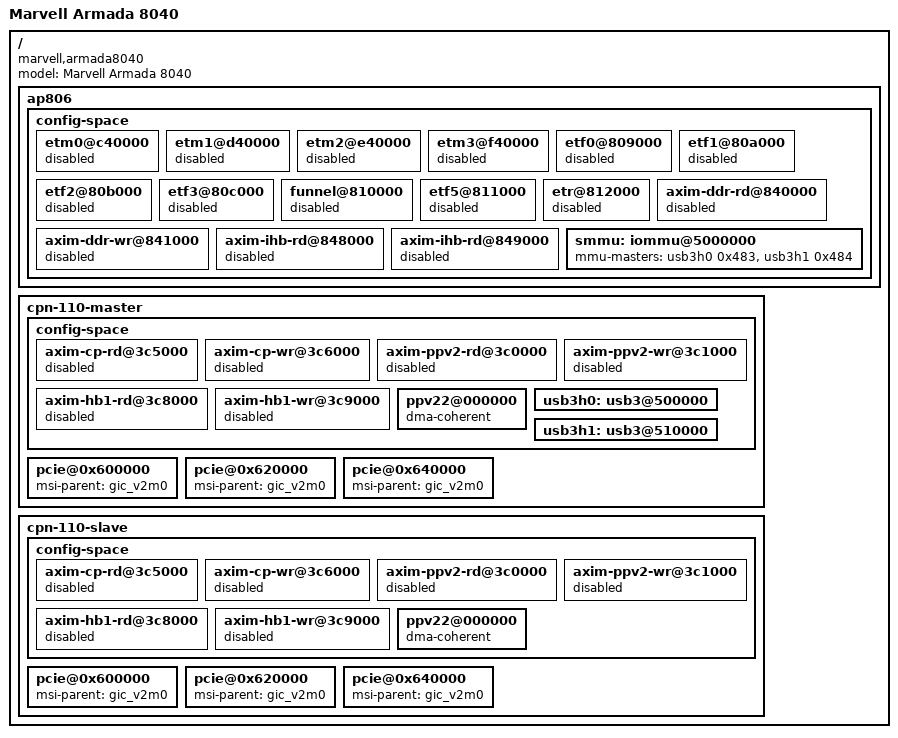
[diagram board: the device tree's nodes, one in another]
/*
 * Copyright (C) 2016 Marvell Technology Group Ltd.
 *
 * This file is dual-licensed: you can use it either under the terms
 * of the GPLv2 or the X11 license, at your option. Note that this dual
 * licensing only applies to this file, and not this project as a
 * whole.
 *
 *  a) This library is free software; you can redistribute it and/or
 *     modify it under the terms of the GNU General Public License as
 *     published by the Free Software Foundation; either version 2 of the
 *     License, or (at your option) any later version.
 *
 *     This library is distributed in the hope that it will be useful,
 *     but WITHOUT ANY WARRANTY; without even the implied warranty of
 *     MERCHANTABILITY or FITNESS FOR A PARTICULAR PURPOSE.  See the
 *     GNU General Public License for more details.
 *
 * Or, alternatively,
 *
 *  b) Permission is hereby granted, free of charge, to any person
 *     obtaining a copy of this software and associated documentation
 *     files (the "Software"), to deal in the Software without
 *     restriction, including without limitation the rights to use,
 *     copy, modify, merge, publish, distribute, sublicense, and/or
 *     sell copies of the Software, and to permit persons to whom the
 *     Software is furnished to do so, subject to the following
 *     conditions:
 *
 *     The above copyright notice and this permission notice shall be
 *     included in all copies or substantial portions of the Software.
 *
 *     THE SOFTWARE IS PROVIDED "AS IS", WITHOUT WARRANTY OF ANY KIND,
 *     EXPRESS OR IMPLIED, INCLUDING BUT NOT LIMITED TO THE WARRANTIES
 *     OF MERCHANTABILITY, FITNESS FOR A PARTICULAR PURPOSE AND
 *     NONINFRINGEMENT. IN NO EVENT SHALL THE AUTHORS OR COPYRIGHT
 *     HOLDERS BE LIABLE FOR ANY CLAIM, DAMAGES OR OTHER LIABILITY,
 *     WHETHER IN AN ACTION OF CONTRACT, TORT OR OTHERWISE, ARISING
 *     FROM, OUT OF OR IN CONNECTION WITH THE SOFTWARE OR THE USE OR
 *     OTHER DEALINGS IN THE SOFTWARE.
 */

/*
 * Device Tree file for the Armada 8040 SoC, made of an AP806 Quad and
 * two CP110.
 */

#include "armada-ap806-quad.dtsi"
#include "armada-cp110-master.dtsi"
#include "armada-cp110-slave.dtsi"

/ {
	model = "Marvell Armada 8040";
	compatible = "marvell,armada8040", "marvell,armada-ap806-quad",
	             "marvell,armada-ap806";

	ap806 {
		config-space {
			/* Temp: disable all Coresight nodes */
			etm0@c40000 {
				status = "disabled";
			};
			etm1@d40000 {
				status = "disabled";
			};
			etm2@e40000 {
				status = "disabled";
			};
			etm3@f40000 {
				status = "disabled";
			};
			etf0@809000 {
				status = "disabled";
			};
			etf1@80a000 {
				status = "disabled";
			};
			etf2@80b000 {
				status = "disabled";
			};
			etf3@80c000 {
				status = "disabled";
			};
			funnel@810000 {
				status = "disabled";
			};
			etf5@811000 {
				status = "disabled";
			};
			etr@812000 {
				status = "disabled";
			};
			axim-ddr-rd@840000 {
				status = "disabled";
			};
			axim-ddr-wr@841000 {
				status = "disabled";
			};
			axim-ihb-rd@848000 {
				status = "disabled";
			};
			axim-ihb-rd@849000 {
				status = "disabled";
			};
			smmu: iommu@5000000 {
				mmu-masters = <&usb3h0 0x483>,
					      <&usb3h1 0x484>;
			};
		};
	};

	cpn-110-master {
		config-space {
			/* Temp: disable all Coresight nodes */
			axim-cp-rd@3c5000 {
				status = "disabled";
			};
			axim-cp-wr@3c6000 {
				status = "disabled";
			};
			axim-ppv2-rd@3c0000 {
				status = "disabled";
			};
			axim-ppv2-wr@3c1000 {
				status = "disabled";
			};
			axim-hb1-rd@3c8000 {
				status = "disabled";
			};
			axim-hb1-wr@3c9000 {
				status = "disabled";
			};
			ppv22@000000 {
				dma-coherent;
			};
			usb3h0: usb3@500000 {
				#stream-id-cells = <1>;
			};
			usb3h1: usb3@510000 {
				#stream-id-cells = <1>;
			};
		};
		pcie@0x600000 {
			msi-parent = <&gic_v2m0>;
		};
		pcie@0x620000 {
			msi-parent = <&gic_v2m0>;
		};
		pcie@0x640000 {
			msi-parent = <&gic_v2m0>;
		};
	};
	cpn-110-slave {
		config-space {
			/* Temp: disable all Coresight nodes */
			axim-cp-rd@3c5000 {
				status = "disabled";
			};
			axim-cp-wr@3c6000 {
				status = "disabled";
			};
			axim-ppv2-rd@3c0000 {
				status = "disabled";
			};
			axim-ppv2-wr@3c1000 {
				status = "disabled";
			};
			axim-hb1-rd@3c8000 {
				status = "disabled";
			};
			axim-hb1-wr@3c9000 {
				status = "disabled";
			};
			ppv22@000000 {
				dma-coherent;
			};
		};
		pcie@0x600000 {
			msi-parent = <&gic_v2m0>;
		};
		pcie@0x620000 {
			msi-parent = <&gic_v2m0>;
		};
		pcie@0x640000 {
			msi-parent = <&gic_v2m0>;
		};
	};
};
